# STM32L4P5 register map
File version: 1.8
CPU: CM4 r0p1, little endian, MPU, FPU, 4 interrupt priority bits
Registers are 32-bit, read-write, reset 0x0 unless marked. A register's access mark holds for its fields unless they carry their own. Offsets are from the block's base; [hi:lo] are bit positions; {n}, {i} and the like mark numbered series; 'fields as' and 'values as' point back to an identical list.

## SYSCFG — System configuration controller
Base 0x40010000
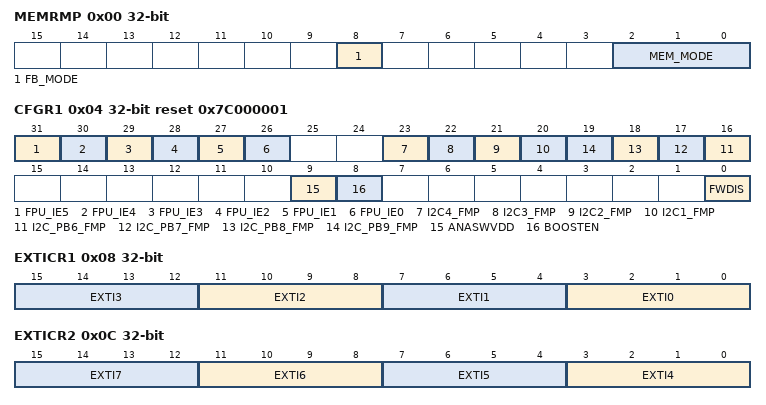
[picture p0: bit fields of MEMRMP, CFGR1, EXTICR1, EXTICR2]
0x00 MEMRMP — memory remap register
  [8] FB_MODE — Flash Bank mode selection
    0=Normal (Flash Bank 1 mapped at 0x0800 0000 (and aliased @0x0000 0000(1)) and Flash Bank 2 mapped at offset); 1=Inverted (Flash Bank 2 mapped at 0x0800 0000 (and aliased @0x0000 0000(1)) and Flash Bank 1 mapped at offset)
  [2:0] MEM_MODE — Memory mapping selection
    0=Main Flash memory mapped at 0x00000000; 1=System Flash memory mapped at 0x00000000; 2=FMC (FMC bank 1 (NOR/PSRAM 1 and 2) mapped at 0x00000000); 3=SRAM1 (SRAM1 mapped at 0x00000000); 4=OCTOSPI1 (OCTOSPI1 memory mapped at 0x00000000); 5=OCTOSPI2 (OCTOSPI2 memory mapped at 0x00000000)
0x04 CFGR1 reset 0x7C000001 — configuration register 1
  [31] FPU_IE5 — Inexact interrupt enable
    0=Disabled (Interrupt disabled); 1=Enabled (Interrupt enabled)
  [30] FPU_IE4 — Input denormal interrupt enable
    values as FPU_IE5
  [29] FPU_IE3 — Overflow interrupt enable
    values as FPU_IE5
  [28] FPU_IE2 — Underflow interrupt enable
    values as FPU_IE5
  [27] FPU_IE1 — Divide-by-zero interrupt enable
    values as FPU_IE5
  [26] FPU_IE0 — Invalid operation interrupt enable
    values as FPU_IE5
  [23] I2C4_FMP — I2C3 Fast-mode Plus driving capability activation
    0=Disabled (Fm+ mode is not enabled on I2Cx pins selected through AF selection bits); 1=Enabled (Fm+ mode is enabled on I2Cx pins selected through AF selection bits)
  [22] I2C3_FMP — I2C3 Fast-mode Plus driving capability activation
    values as I2C4_FMP
  [21] I2C2_FMP — I2C2 Fast-mode Plus driving capability activation
    values as I2C4_FMP
  [20] I2C1_FMP — I2C1 Fast-mode Plus driving capability activation
    values as I2C4_FMP
  [n+10] I2C_PB{n}_FMP (n=6..9) — Fast-mode Plus (Fm+) driving capability activation on PB{n}
    0=Disabled (PBx pin operates in standard mode); 1=Enabled (Fm+ mode enabled on PB7 pin, and the Speed control is bypassed)
  [9] ANASWVDD — GPIO analog switch control voltage selection when at least one analog peripheral supplied by VDDA is enabled (COMP, OPAMP, VREFBUF, ADC,...)
    0=VDDA (I/O analog switches supplied by VDDA or booster when booster is ON); 1=VDD (I/O analog switches supplied by VDD)
  [8] BOOSTEN — I/O analog switch voltage booster enable
    0=Disabled (I/O analog switches are supplied by VDDA voltage. This is the recommended configuration when using the ADC in high VDDA voltage operation); 1=Enabled (I/O analog switches are supplied by a dedicated voltage booster (supplied by VDD). This is the recommended configuration when using the ADC in low VDDA voltage operation)
  [0] FWDIS — Firewall disable
    0=Enabled (Firewall protection enabled); 1=Disabled (Firewall protection disabled)
0x08 EXTICR1 — external interrupt configuration register 1
  [all] fields
    0=PA (Select PAx as the source input for the EXTIx external interrupt); 1=PB (Select PBx as the source input for the EXTIx external interrupt); 2=PC (Select PCx as the source input for the EXTIx external interrupt); 3=PD (Select PDx as the source input for the EXTIx external interrupt); 4=PE (Select PEx as the source input for the EXTIx external interrupt); 5=PF (Select PFx as the source input for the EXTIx external interrupt); 6=PG (Select PGx as the source input for the EXTIx external interrupt); 7=PH (Select PHx as the source input for the EXTIx external interrupt); 8=PI (Select PIx as the source input for the EXTIx external interrupt)
  [4n+3:4n] EXTI{n} (n=0..3) — EXTI {n} configuration bits
0x0C EXTICR2 — external interrupt configuration register 2
  [all] fields
    values as the fields of EXTICR1
  [4n-13:4n-16] EXTI{n} (n=4..7) — EXTI {n} configuration bits
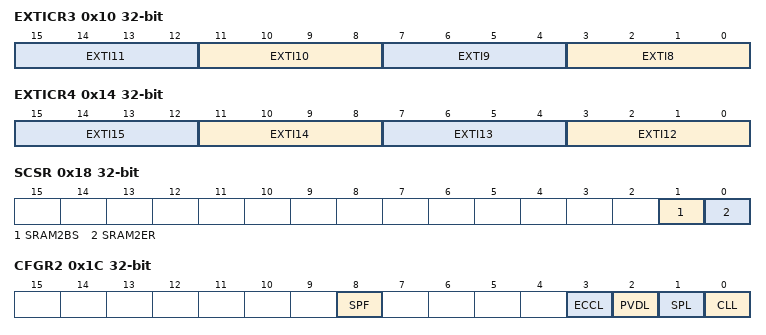
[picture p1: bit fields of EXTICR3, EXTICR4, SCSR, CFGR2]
0x10 EXTICR3 — external interrupt configuration register 3
  [all] fields
    values as the fields of EXTICR1
  [4n-29:4n-32] EXTI{n} (n=8..11) — EXTI {n} configuration bits
0x14 EXTICR4 — external interrupt configuration register 4
  [all] fields
    0=PA (Select PAx as the source input for the EXTIx external interrupt); 1=PB (Select PBx as the source input for the EXTIx external interrupt); 2=PC (Select PCx as the source input for the EXTIx external interrupt); 3=PD (Select PDx as the source input for the EXTIx external interrupt); 4=PE (Select PEx as the source input for the EXTIx external interrupt); 5=PF (Select PFx as the source input for the EXTIx external interrupt); 6=PG (Select PGx as the source input for the EXTIx external interrupt); 7=PH (Select PHx as the source input for the EXTIx external interrupt)
  [4n-45:4n-48] EXTI{n} (n=12..15) — EXTI{n} configuration bits
0x18 SCSR access per field
  [1] SRAM2BS ro — SRAM2 busy by erase operation
    0=NotBusy (No SRAM2 erase operation is on going); 1=Busy (SRAM2 erase operation is on going)
  [0] SRAM2ER rw — SRAM2 Erase
    1=Erase (Setting this bit starts a hardware SRAM2 erase operation)
0x1C CFGR2 access per field
  [8] SPF rw — SRAM2 parity error flag
    0=Cleared (No SRAM2 parity error detected); 1=Set (SRAM2 parity error detected)
  [3] ECCL wo — ECC Lock
    0=Disconnected (ECC error disconnected from TIM1/8/15/16/17 Break input); 1=Connected (ECC error connected to TIM1/8/15/16/17 Break input)
  [2] PVDL wo — PVD lock enable bit
    0=Disconnected (PVD interrupt disconnected from TIM1/8/15/16/17 Break input. PVDE and PLS[2:0] bits can be programmed by the application); 1=Connected (PVD interrupt connected to TIM1/8/15/16/17 Break input, PVDE and PLS[2:0] bits are read only)
  [1] SPL wo — SRAM2 parity lock bit
    0=Disconnected (SRAM2 parity error signal disconnected from TIM1/8/15/16/17 Break inputs); 1=Connected (SRAM2 parity error signal connected to TIM1/8/15/16/17 Break inputs)
  [0] CLL wo — Cortex-M4 LOCKUP (Hardfault) output enable bit
    0=Disconnected (Cortex®-M4 LOCKUP output disconnected from TIM1/8/15/16/17 Break inputs); 1=Connected (Cortex®-M4 LOCKUP output connected to TIM1/8/15/16/17 Break inputs)
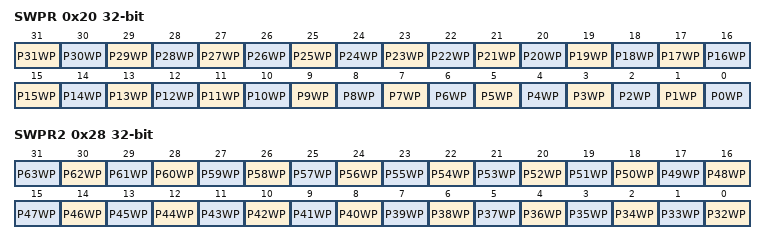
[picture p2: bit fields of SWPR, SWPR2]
0x20 SWPR wo
  [all] fields
    0=Disabled (Write protection of SRAM2 page x is disabled); 1=Enabled (Write protection of SRAM2 page x is enabled)
  [31] P31WP — SRAM2 page 31 write protection
  [n] P{n}WP (n=0..30)
0x24 SKR wo
  [7:0] KEY — SRAM2 write protection key for software erase
    83=2. Write 0x53 into Key[7:0]; 202=1. Write 0xCA into Key[7:0]
0x28 SWPR2 access not given — write protection register 2
  [all] fields
    values as the fields of SWPR
  [n-32] P{n}WP (n=32..63) — SRAM2 page x write protection
